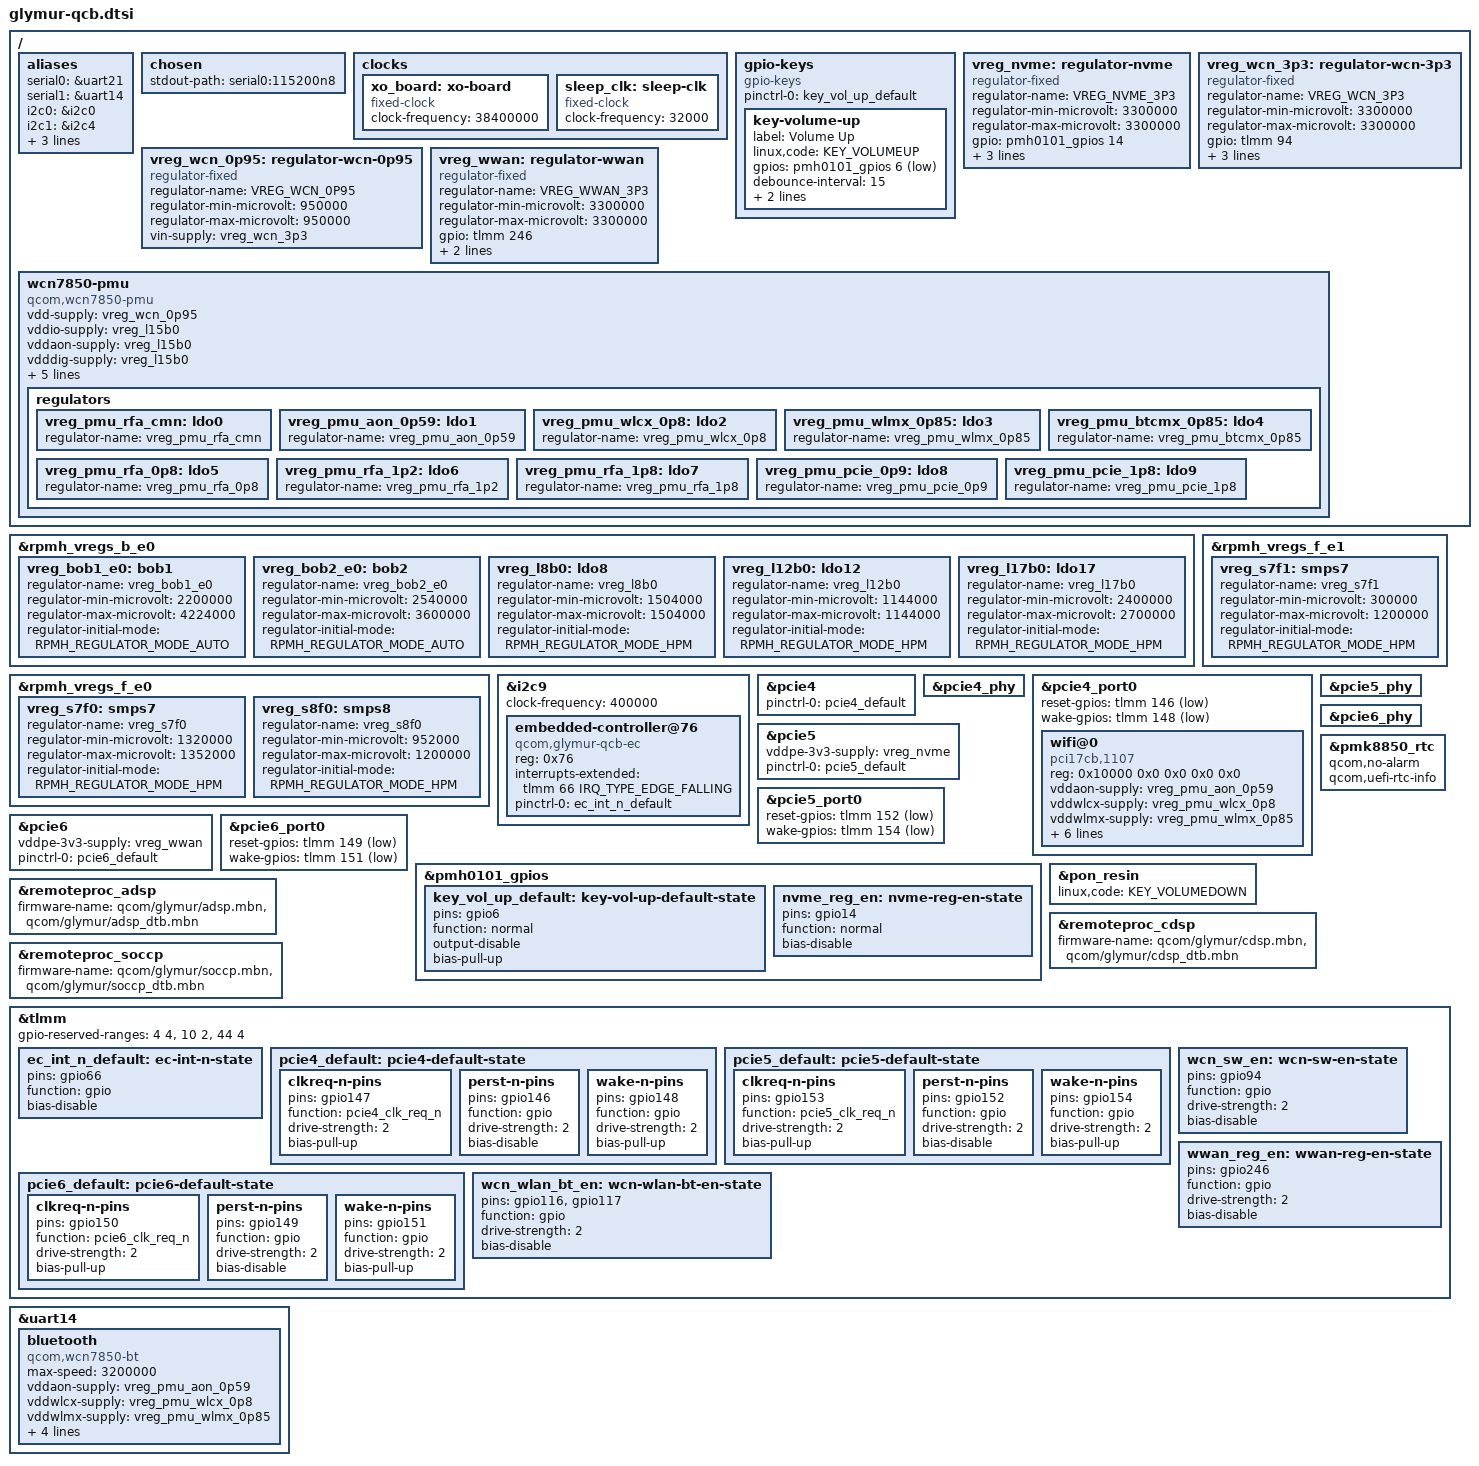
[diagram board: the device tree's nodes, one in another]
// SPDX-License-Identifier: BSD-3-Clause
/*
 * Copyright (c) Qualcomm Technologies, Inc. and/or its subsidiaries.
 */

/ {
	aliases {
		serial0 = &uart21;
		serial1 = &uart14;
		i2c0 = &i2c0;
		i2c1 = &i2c4;
		i2c2 = &i2c5;
		i2c3 = &i2c9;
		spi0 = &spi18;
	};

	chosen {
		stdout-path = "serial0:115200n8";
	};

	clocks {
		xo_board: xo-board {
			compatible = "fixed-clock";
			clock-frequency = <38400000>;
			#clock-cells = <0>;
		};

		sleep_clk: sleep-clk {
			compatible = "fixed-clock";
			clock-frequency = <32000>;
			#clock-cells = <0>;
		};
	};

	gpio-keys {
		compatible = "gpio-keys";

		pinctrl-0 = <&key_vol_up_default>;
		pinctrl-names = "default";

		key-volume-up {
			label = "Volume Up";
			linux,code = <KEY_VOLUMEUP>;
			gpios = <&pmh0101_gpios 6 GPIO_ACTIVE_LOW>;
			debounce-interval = <15>;
			linux,can-disable;
			wakeup-source;
		};
	};

	vreg_nvme: regulator-nvme {
		compatible = "regulator-fixed";

		regulator-name = "VREG_NVME_3P3";
		regulator-min-microvolt = <3300000>;
		regulator-max-microvolt = <3300000>;

		gpio = <&pmh0101_gpios 14 GPIO_ACTIVE_HIGH>;
		enable-active-high;

		pinctrl-0 = <&nvme_reg_en>;
		pinctrl-names = "default";

		regulator-boot-on;
	};

	vreg_wcn_0p95: regulator-wcn-0p95 {
		compatible = "regulator-fixed";

		regulator-name = "VREG_WCN_0P95";
		regulator-min-microvolt = <950000>;
		regulator-max-microvolt = <950000>;

		vin-supply = <&vreg_wcn_3p3>;
	};

	vreg_wcn_3p3: regulator-wcn-3p3 {
		compatible = "regulator-fixed";

		regulator-name = "VREG_WCN_3P3";
		regulator-min-microvolt = <3300000>;
		regulator-max-microvolt = <3300000>;

		gpio = <&tlmm 94 GPIO_ACTIVE_HIGH>;
		enable-active-high;

		pinctrl-0 = <&wcn_sw_en>;
		pinctrl-names = "default";

		regulator-boot-on;
	};

	vreg_wwan: regulator-wwan {
		compatible = "regulator-fixed";

		regulator-name = "VREG_WWAN_3P3";
		regulator-min-microvolt = <3300000>;
		regulator-max-microvolt = <3300000>;

		gpio = <&tlmm 246 GPIO_ACTIVE_HIGH>;
		enable-active-high;

		pinctrl-0 = <&wwan_reg_en>;
		pinctrl-names = "default";
	};

	wcn7850-pmu {
		compatible = "qcom,wcn7850-pmu";

		vdd-supply = <&vreg_wcn_0p95>;
		vddio-supply = <&vreg_l15b0>;
		vddaon-supply = <&vreg_l15b0>;
		vdddig-supply = <&vreg_l15b0>;
		vddrfa1p2-supply = <&vreg_l15b0>;
		vddrfa1p8-supply = <&vreg_l15b0>;

		wlan-enable-gpios = <&tlmm 117 GPIO_ACTIVE_HIGH>;
		bt-enable-gpios = <&tlmm 116 GPIO_ACTIVE_HIGH>;

		pinctrl-0 = <&wcn_wlan_bt_en>;
		pinctrl-names = "default";

		regulators {
			vreg_pmu_rfa_cmn: ldo0 {
				regulator-name = "vreg_pmu_rfa_cmn";
			};

			vreg_pmu_aon_0p59: ldo1 {
				regulator-name = "vreg_pmu_aon_0p59";
			};

			vreg_pmu_wlcx_0p8: ldo2 {
				regulator-name = "vreg_pmu_wlcx_0p8";
			};

			vreg_pmu_wlmx_0p85: ldo3 {
				regulator-name = "vreg_pmu_wlmx_0p85";
			};

			vreg_pmu_btcmx_0p85: ldo4 {
				regulator-name = "vreg_pmu_btcmx_0p85";
			};

			vreg_pmu_rfa_0p8: ldo5 {
				regulator-name = "vreg_pmu_rfa_0p8";
			};

			vreg_pmu_rfa_1p2: ldo6 {
				regulator-name = "vreg_pmu_rfa_1p2";
			};

			vreg_pmu_rfa_1p8: ldo7 {
				regulator-name = "vreg_pmu_rfa_1p8";
			};

			vreg_pmu_pcie_0p9: ldo8 {
				regulator-name = "vreg_pmu_pcie_0p9";
			};

			vreg_pmu_pcie_1p8: ldo9 {
				regulator-name = "vreg_pmu_pcie_1p8";
			};
		};
	};
};

&rpmh_vregs_b_e0 {
	vreg_bob1_e0: bob1 {
		regulator-name = "vreg_bob1_e0";
		regulator-min-microvolt = <2200000>;
		regulator-max-microvolt = <4224000>;
		regulator-initial-mode = <RPMH_REGULATOR_MODE_AUTO>;
	};

	vreg_bob2_e0: bob2 {
		regulator-name = "vreg_bob2_e0";
		regulator-min-microvolt = <2540000>;
		regulator-max-microvolt = <3600000>;
		regulator-initial-mode = <RPMH_REGULATOR_MODE_AUTO>;
	};

	vreg_l8b0: ldo8 {
		regulator-name = "vreg_l8b0";
		regulator-min-microvolt = <1504000>;
		regulator-max-microvolt = <1504000>;
		regulator-initial-mode = <RPMH_REGULATOR_MODE_HPM>;
	};

	vreg_l12b0: ldo12 {
		regulator-name = "vreg_l12b0";
		regulator-min-microvolt = <1144000>;
		regulator-max-microvolt = <1144000>;
		regulator-initial-mode = <RPMH_REGULATOR_MODE_HPM>;
	};

	vreg_l17b0: ldo17 {
		regulator-name = "vreg_l17b0";
		regulator-min-microvolt = <2400000>;
		regulator-max-microvolt = <2700000>;
		regulator-initial-mode = <RPMH_REGULATOR_MODE_HPM>;
	};
};

&rpmh_vregs_f_e0 {
	vreg_s7f0: smps7 {
		regulator-name = "vreg_s7f0";
		regulator-min-microvolt = <1320000>;
		regulator-max-microvolt = <1352000>;
		regulator-initial-mode = <RPMH_REGULATOR_MODE_HPM>;
	};

	vreg_s8f0: smps8 {
		regulator-name = "vreg_s8f0";
		regulator-min-microvolt = <952000>;
		regulator-max-microvolt = <1200000>;
		regulator-initial-mode = <RPMH_REGULATOR_MODE_HPM>;
	};
};

&rpmh_vregs_f_e1 {
	vreg_s7f1: smps7 {
		regulator-name = "vreg_s7f1";
		regulator-min-microvolt = <300000>;
		regulator-max-microvolt = <1200000>;
		regulator-initial-mode = <RPMH_REGULATOR_MODE_HPM>;
	};
};

&i2c9 {
	clock-frequency = <400000>;

	status = "okay";

	embedded-controller@76 {
		compatible = "qcom,glymur-qcb-ec", "qcom,hamoa-crd-ec";
		reg = <0x76>;

		interrupts-extended = <&tlmm 66 IRQ_TYPE_EDGE_FALLING>;

		pinctrl-0 = <&ec_int_n_default>;
		pinctrl-names = "default";
	};
};

&pcie4 {
	pinctrl-0 = <&pcie4_default>;
	pinctrl-names = "default";

	status = "okay";
};

&pcie4_phy {
	status = "okay";
};

&pcie4_port0 {
	reset-gpios = <&tlmm 146 GPIO_ACTIVE_LOW>;
	wake-gpios = <&tlmm 148 GPIO_ACTIVE_LOW>;

	wifi@0 {
		compatible = "pci17cb,1107";
		reg = <0x10000 0x0 0x0 0x0 0x0>;

		vddaon-supply = <&vreg_pmu_aon_0p59>;
		vddwlcx-supply = <&vreg_pmu_wlcx_0p8>;
		vddwlmx-supply = <&vreg_pmu_wlmx_0p85>;
		vddrfacmn-supply = <&vreg_pmu_rfa_cmn>;
		vddrfa0p8-supply = <&vreg_pmu_rfa_0p8>;
		vddrfa1p2-supply = <&vreg_pmu_rfa_1p2>;
		vddrfa1p8-supply = <&vreg_pmu_rfa_1p8>;
		vddpcie0p9-supply = <&vreg_pmu_pcie_0p9>;
		vddpcie1p8-supply = <&vreg_pmu_pcie_1p8>;
	};
};

&pcie5 {
	vddpe-3v3-supply = <&vreg_nvme>;

	pinctrl-0 = <&pcie5_default>;
	pinctrl-names = "default";

	status = "okay";
};

&pcie5_phy {
	status = "okay";
};

&pcie5_port0 {
	reset-gpios = <&tlmm 152 GPIO_ACTIVE_LOW>;
	wake-gpios = <&tlmm 154 GPIO_ACTIVE_LOW>;
};

&pcie6 {
	vddpe-3v3-supply = <&vreg_wwan>;

	pinctrl-0 = <&pcie6_default>;
	pinctrl-names = "default";

	status = "okay";
};

&pcie6_phy {
	status = "okay";
};

&pcie6_port0 {
	reset-gpios = <&tlmm 149 GPIO_ACTIVE_LOW>;
	wake-gpios = <&tlmm 151 GPIO_ACTIVE_LOW>;
};

&pmh0101_gpios {
	key_vol_up_default: key-vol-up-default-state {
		pins = "gpio6";
		function = "normal";
		output-disable;
		bias-pull-up;
	};

	nvme_reg_en: nvme-reg-en-state {
		pins = "gpio14";
		function = "normal";
		bias-disable;
	};
};

&pmk8850_rtc {
	qcom,no-alarm;
	qcom,uefi-rtc-info;
};

&pon_resin {
	linux,code = <KEY_VOLUMEDOWN>;

	status = "okay";
};

&remoteproc_adsp {
	firmware-name = "qcom/glymur/adsp.mbn",
			"qcom/glymur/adsp_dtb.mbn";

	status = "okay";
};

&remoteproc_cdsp {
	firmware-name = "qcom/glymur/cdsp.mbn",
			"qcom/glymur/cdsp_dtb.mbn";

	status = "okay";
};

&remoteproc_soccp {
	firmware-name = "qcom/glymur/soccp.mbn",
			"qcom/glymur/soccp_dtb.mbn";
};

&tlmm {
	gpio-reserved-ranges = <4 4>, /* EC TZ Secure I3C */
			       <10 2>, /* OOB UART */
			       <44 4>; /* Security SPI (TPM) */

	ec_int_n_default: ec-int-n-state {
		pins = "gpio66";
		function = "gpio";
		bias-disable;
	};

	pcie4_default: pcie4-default-state {
		clkreq-n-pins {
			pins = "gpio147";
			function = "pcie4_clk_req_n";
			drive-strength = <2>;
			bias-pull-up;
		};

		perst-n-pins {
			pins = "gpio146";
			function = "gpio";
			drive-strength = <2>;
			bias-disable;
		};

		wake-n-pins {
			pins = "gpio148";
			function = "gpio";
			drive-strength = <2>;
			bias-pull-up;
		};
	};

	pcie5_default: pcie5-default-state {
		clkreq-n-pins {
			pins = "gpio153";
			function = "pcie5_clk_req_n";
			drive-strength = <2>;
			bias-pull-up;
		};

		perst-n-pins {
			pins = "gpio152";
			function = "gpio";
			drive-strength = <2>;
			bias-disable;
		};

		wake-n-pins {
			pins = "gpio154";
			function = "gpio";
			drive-strength = <2>;
			bias-pull-up;
		};
	};

	pcie6_default: pcie6-default-state {
		clkreq-n-pins {
			pins = "gpio150";
			function = "pcie6_clk_req_n";
			drive-strength = <2>;
			bias-pull-up;
		};

		perst-n-pins {
			pins = "gpio149";
			function = "gpio";
			drive-strength = <2>;
			bias-disable;
		};

		wake-n-pins {
			pins = "gpio151";
			function = "gpio";
			drive-strength = <2>;
			bias-pull-up;
		};
	};

	wcn_wlan_bt_en: wcn-wlan-bt-en-state {
		pins = "gpio116", "gpio117";
		function = "gpio";
		drive-strength = <2>;
		bias-disable;
	};

	wcn_sw_en: wcn-sw-en-state {
		pins = "gpio94";
		function = "gpio";
		drive-strength = <2>;
		bias-disable;
	};

	wwan_reg_en: wwan-reg-en-state {
		pins = "gpio246";
		function = "gpio";
		drive-strength = <2>;
		bias-disable;
	};
};

&uart14 {
	status = "okay";

	bluetooth {
		compatible = "qcom,wcn7850-bt";
		max-speed = <3200000>;

		vddaon-supply = <&vreg_pmu_aon_0p59>;
		vddwlcx-supply = <&vreg_pmu_wlcx_0p8>;
		vddwlmx-supply = <&vreg_pmu_wlmx_0p85>;
		vddrfacmn-supply = <&vreg_pmu_rfa_cmn>;
		vddrfa0p8-supply = <&vreg_pmu_rfa_0p8>;
		vddrfa1p2-supply = <&vreg_pmu_rfa_1p2>;
		vddrfa1p8-supply = <&vreg_pmu_rfa_1p8>;
	};
};
